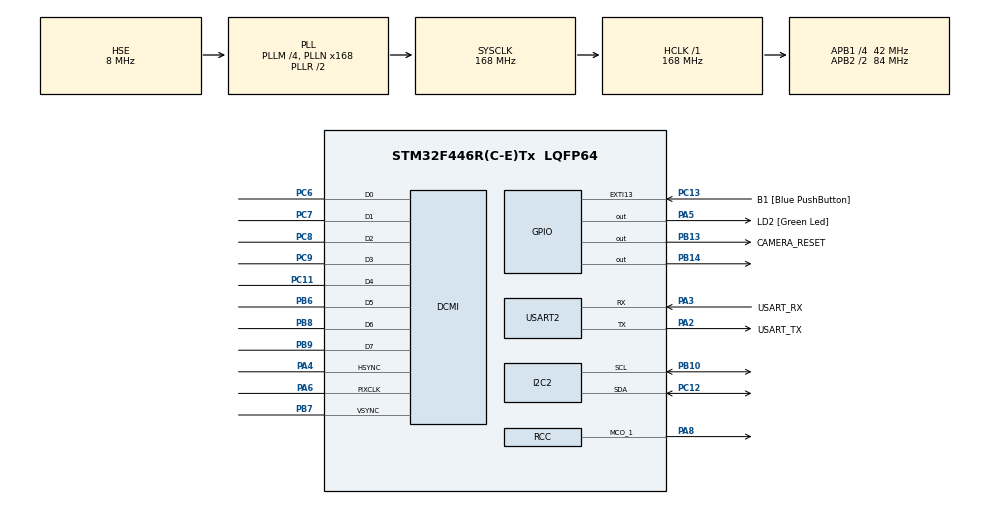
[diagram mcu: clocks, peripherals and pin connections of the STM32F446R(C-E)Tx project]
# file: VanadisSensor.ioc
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DCMI.JPEGMode=DCMI_JPEG_DISABLE
DCMI.PCKPolarity=DCMI_PCKPOLARITY_RISING
DCMI.VSPolarity=DCMI_VSPOLARITY_HIGH
Dma.DCMI.0.Direction=DMA_PERIPH_TO_MEMORY
Dma.DCMI.0.FIFOMode=DMA_FIFOMODE_DISABLE
Dma.DCMI.0.Instance=DMA2_Stream1
Dma.DCMI.0.MemDataAlignment=DMA_MDATAALIGN_WORD
Dma.DCMI.0.MemInc=DMA_MINC_ENABLE
Dma.DCMI.0.Mode=DMA_NORMAL
Dma.DCMI.0.PeriphDataAlignment=DMA_PDATAALIGN_WORD
Dma.DCMI.0.PeriphInc=DMA_PINC_DISABLE
Dma.DCMI.0.Priority=DMA_PRIORITY_LOW
Dma.Request0=DCMI
Mcu.Family=STM32F4
Mcu.Name=STM32F446R(C-E)Tx
Mcu.Package=LQFP64
NVIC.DCMI_IRQn=true\:0\:0\:false\:false\:true\:true\:true\:true
NVIC.DMA2_Stream1_IRQn=true\:0\:0\:false\:false\:true\:false\:true\:true
NVIC.PriorityGroup=NVIC_PRIORITYGROUP_0
PA13.GPIO_Label=TMS
PA13.Mode=Serial_Wire
PA13.Signal=SYS_JTMS-SWDIO
PA14.GPIO_Label=TCK
PA14.Mode=Serial_Wire
PA14.Signal=SYS_JTCK-SWCLK
PA2.GPIO_Label=USART_TX
PA2.Mode=Asynchronous
PA2.Signal=USART2_TX
PA3.GPIO_Label=USART_RX
PA3.Mode=Asynchronous
PA3.Signal=USART2_RX
PA4.GPIO_PuPd=GPIO_PULLDOWN
PA4.GPIO_Speed=GPIO_SPEED_FREQ_VERY_HIGH
PA4.Mode=Slave_8_bits_External_Synchro
PA4.Signal=DCMI_HSYNC
PA5.GPIO_Label=LD2 [Green Led]
PA5.Signal=GPIO_Output
PA6.GPIO_PuPd=GPIO_PULLDOWN
PA6.GPIO_Speed=GPIO_SPEED_FREQ_VERY_HIGH
PA6.Mode=Slave_8_bits_External_Synchro
PA6.Signal=DCMI_PIXCLK
PA8.GPIO_Speed=GPIO_SPEED_FREQ_VERY_HIGH
PA8.Mode=Clock-out-1
PA8.Signal=RCC_MCO_1
PB10.GPIO_Pu=GPIO_PULLUP
PB10.GPIO_Speed=GPIO_SPEED_FREQ_VERY_HIGH
PB10.Mode=I2C
PB10.Signal=I2C2_SCL
PB13.GPIO_Label=CAMERA_RESET
PB13.Signal=GPIO_Output
PB14.Signal=GPIO_Output
PB3.GPIO_Label=SWO
PB3.Signal=SYS_JTDO-SWO
PB6.GPIO_PuPd=GPIO_PULLDOWN
PB6.GPIO_Speed=GPIO_SPEED_FREQ_VERY_HIGH
PB6.Mode=Slave_8_bits_External_Synchro
PB6.Signal=DCMI_D5
PB7.GPIO_PuPd=GPIO_PULLDOWN
PB7.GPIO_Speed=GPIO_SPEED_FREQ_VERY_HIGH
PB7.Mode=Slave_8_bits_External_Synchro
PB7.Signal=DCMI_VSYNC
PB8.GPIO_PuPd=GPIO_PULLDOWN
PB8.GPIO_Speed=GPIO_SPEED_FREQ_VERY_HIGH
PB8.Mode=Slave_8_bits_External_Synchro
PB8.Signal=DCMI_D6
PB9.GPIO_PuPd=GPIO_PULLDOWN
PB9.GPIO_Speed=GPIO_SPEED_FREQ_VERY_HIGH
PB9.Mode=Slave_8_bits_External_Synchro
PB9.Signal=DCMI_D7
PC11.GPIO_PuPd=GPIO_PULLDOWN
PC11.GPIO_Speed=GPIO_SPEED_FREQ_VERY_HIGH
PC11.Mode=Slave_8_bits_External_Synchro
PC11.Signal=DCMI_D4
PC12.GPIO_Pu=GPIO_PULLUP
PC12.GPIO_Speed=GPIO_SPEED_FREQ_VERY_HIGH
PC12.Mode=I2C
PC12.Signal=I2C2_SDA
PC13.GPIO_Label=B1 [Blue PushButton]
PC13.GPIO_ModeDefaultEXTI=GPIO_MODE_IT_FALLING
PC13.Signal=GPXTI13
PC14-OSC32_IN.Signal=RCC_OSC32_IN
PC15-OSC32_OUT.Signal=RCC_OSC32_OUT
PC6.GPIO_PuPd=GPIO_PULLDOWN
PC6.GPIO_Speed=GPIO_SPEED_FREQ_VERY_HIGH
PC6.Mode=Slave_8_bits_External_Synchro
PC6.Signal=DCMI_D0
PC7.GPIO_PuPd=GPIO_PULLDOWN
PC7.GPIO_Speed=GPIO_SPEED_FREQ_VERY_HIGH
PC7.Mode=Slave_8_bits_External_Synchro
PC7.Signal=DCMI_D1
PC8.GPIO_PuPd=GPIO_PULLDOWN
PC8.GPIO_Speed=GPIO_SPEED_FREQ_VERY_HIGH
PC8.Mode=Slave_8_bits_External_Synchro
PC8.Signal=DCMI_D2
PC9.GPIO_PuPd=GPIO_PULLDOWN
PC9.GPIO_Speed=GPIO_SPEED_FREQ_VERY_HIGH
PC9.Mode=Slave_8_bits_External_Synchro
PC9.Signal=DCMI_D3
PH0-OSC_IN.Mode=HSE-External-Oscillator
PH0-OSC_IN.Signal=RCC_OSC_IN
PH1-OSC_OUT.Mode=HSE-External-Oscillator
PH1-OSC_OUT.Signal=RCC_OSC_OUT
ProjectManager.HeapSize=0x200
ProjectManager.StackSize=0x400
ProjectManager.TargetToolchain=STM32CubeIDE
RCC.48MHZClocksFreq_Value=84000000
RCC.AHBFreq_Value=168000000
RCC.APB1CLKDivider=RCC_HCLK_DIV4
RCC.APB1Freq_Value=42000000
RCC.APB1TimFreq_Value=84000000
RCC.APB2CLKDivider=RCC_HCLK_DIV2
RCC.APB2Freq_Value=84000000
RCC.APB2TimFreq_Value=168000000
RCC.CortexFreq_Value=168000000
RCC.FLatency-AdvancedSettings=FLASH_LATENCY_5
RCC.HCLKFreq_Value=168000000
RCC.HSE_VALUE=8000000
RCC.HSI_VALUE=16000000
RCC.PLLM=4
RCC.PLLN=168
RCC.PLLP=RCC_PLLP_DIV4
RCC.PLLSourceVirtual=RCC_PLLSOURCE_HSE
RCC.RCC_MCO1Source=RCC_MCO1SOURCE_HSE
RCC.SYSCLKFreq_VALUE=168000000
RCC.SYSCLKSource=RCC_SYSCLKSOURCE_PLLRCLK
RCC.USBFreq_Value=168000000
RCC.VCOOutputFreq_Value=336000000
USART2.VirtualMode=VM_ASYNC
board=NUCLEO-F446RE

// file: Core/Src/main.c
/* USER CODE BEGIN Header */
/**
  ******************************************************************************
  * @file           : main.c
  * @brief          : Main program body
  ******************************************************************************
  * @attention
  *
  * Copyright (c) 2025 STMicroelectronics.
  * All rights reserved.
  *
  * This software is licensed under terms that can be found in the LICENSE file
  * in the root directory of this software component.
  * If no LICENSE file comes with this software, it is provided AS-IS.
  *
  ******************************************************************************
  */
/* USER CODE END Header */
#include "main.h"
#include "dcmi.h"
#include "dma.h"
#include "i2c.h"
#include "usart.h"
#include "gpio.h"

/* USER CODE BEGIN Includes */
#include "common.h"
#include "ov7670.h"

/* USER CODE END Includes */

/* USER CODE BEGIN PV */
#define MAX_PICTURE_BUFF     19200
uint16_t pBuffer[MAX_PICTURE_BUFF];
RET init_code= 20;
RET config_code= 20;
/* USER CODE END PV */

void SystemClock_Config(void);

int main(void)
{

  /* MCU Configuration--------------------------------------------------------*/

  /* Reset of all peripherals, Initializes the Flash interface and the Systick. */
  HAL_Init();

  /* Configure the system clock */
  SystemClock_Config();

  /* Initialize all configured peripherals */
  MX_GPIO_Init();
  MX_DMA_Init();
  MX_USART2_UART_Init();
  MX_DCMI_Init();
  MX_I2C2_Init();
  /* USER CODE BEGIN 2 */

  HAL_Delay(1000);
  HAL_GPIO_WritePin(GPIOD, GPIO_PIN_12, GPIO_PIN_RESET); //Camera PWDN to GND
  while (init_code != RET_OK){
	  init_code = ov7670_init(&hdcmi, &hdma_dcmi, &hi2c2);}

  while (config_code != RET_OK){
	  config_code = ov7670_config(OV7670_MODE_QVGA_RGB565);}

  /* USER CODE END 2 */

  /* Infinite loop */
  /* USER CODE BEGIN WHILE */
  while (1)
    {
      HAL_DCMI_Start_DMA(&hdcmi, DCMI_MODE_SNAPSHOT, pBuffer, MAX_PICTURE_BUFF/2);
      HAL_Delay(100);  //Wait for DMA to complete
      // picture pBuffer size 120*160=19200 is now available, we can transmit
      // or display in lcd as shown below
    /* USER CODE END WHILE */

  }
}

void SystemClock_Config(void)
{
  RCC_OscInitTypeDef RCC_OscInitStruct = {0};
  RCC_ClkInitTypeDef RCC_ClkInitStruct = {0};

  /** Configure the main internal regulator output voltage
  */
  __HAL_RCC_PWR_CLK_ENABLE();
  __HAL_PWR_VOLTAGESCALING_CONFIG(PWR_REGULATOR_VOLTAGE_SCALE1);

  /** Initializes the RCC Oscillators according to the specified parameters
  * in the RCC_OscInitTypeDef structure.
  */
  RCC_OscInitStruct.OscillatorType = RCC_OSCILLATORTYPE_HSE;
  RCC_OscInitStruct.HSEState = RCC_HSE_ON;
  RCC_OscInitStruct.PLL.PLLState = RCC_PLL_ON;
  RCC_OscInitStruct.PLL.PLLSource = RCC_PLLSOURCE_HSE;
  RCC_OscInitStruct.PLL.PLLM = 4;
  RCC_OscInitStruct.PLL.PLLN = 168;
  RCC_OscInitStruct.PLL.PLLP = RCC_PLLP_DIV4;
  RCC_OscInitStruct.PLL.PLLQ = 2;
  RCC_OscInitStruct.PLL.PLLR = 2;
  if (HAL_RCC_OscConfig(&RCC_OscInitStruct) != HAL_OK)
  {
    Error_Handler();
  }

  /** Initializes the CPU, AHB and APB buses clocks
  */
  RCC_ClkInitStruct.ClockType = RCC_CLOCKTYPE_HCLK|RCC_CLOCKTYPE_SYSCLK
                              |RCC_CLOCKTYPE_PCLK1|RCC_CLOCKTYPE_PCLK2;
  RCC_ClkInitStruct.SYSCLKSource = RCC_SYSCLKSOURCE_PLLRCLK;
  RCC_ClkInitStruct.AHBCLKDivider = RCC_SYSCLK_DIV1;
  RCC_ClkInitStruct.APB1CLKDivider = RCC_HCLK_DIV4;
  RCC_ClkInitStruct.APB2CLKDivider = RCC_HCLK_DIV2;

  if (HAL_RCC_ClockConfig(&RCC_ClkInitStruct, FLASH_LATENCY_5) != HAL_OK)
  {
    Error_Handler();
  }
  HAL_RCC_MCOConfig(RCC_MCO1, RCC_MCO1SOURCE_HSE, RCC_MCODIV_1);
}

void Error_Handler(void)
{
  __disable_irq();
  while (1)
  {
  }
}
